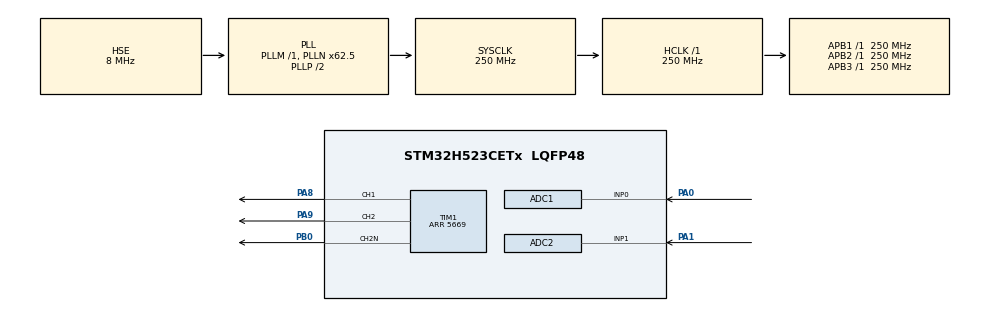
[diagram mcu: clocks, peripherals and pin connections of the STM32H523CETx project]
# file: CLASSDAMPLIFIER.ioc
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ADC1.Channel-0\#ChannelRegularConversion=ADC_CHANNEL_0
ADC1.ContinuousConvMode=DISABLE
ADC1.DMAContinuousRequests=ENABLE
ADC1.ExternalTrigConv=ADC_EXTERNALTRIG_T1_TRGO
ADC1.MonitoredBy-0\#ChannelRegularConversion=__NULL
ADC1.NbrOfConversion=1
ADC1.NbrOfConversionFlag=1
ADC1.OffsetNumber-0\#ChannelRegularConversion=ADC_OFFSET_NONE
ADC1.Rank-0\#ChannelRegularConversion=1
ADC1.SamplingTime-0\#ChannelRegularConversion=ADC_SAMPLETIME_2CYCLES_5
ADC1.master=1
ADC2.Channel-0\#ChannelRegularConversion=ADC_CHANNEL_1
ADC2.ContinuousConvMode=DISABLE
ADC2.EOCSelection=ADC_EOC_SINGLE_CONV
ADC2.MonitoredBy-0\#ChannelRegularConversion=__NULL
ADC2.NbrOfConversion=1
ADC2.NbrOfConversionFlag=1
ADC2.OffsetNumber-0\#ChannelRegularConversion=ADC_OFFSET_NONE
ADC2.Rank-0\#ChannelRegularConversion=1
ADC2.SamplingTime-0\#ChannelRegularConversion=ADC_SAMPLETIME_2CYCLES_5
BOOTPATH.BootPathName=LEGACY
BOOTPATH.UserSelectedBootPath=LEGACY
CORTEX_M33_NS.Number-Cortex_Memory_Protection_Unit_Region0_OTP_RO_AREAS_Settings=MPU_REGION_NUMBER0
CORTEX_M33_NS.default_mode_Activation=1
CORTEX_M33_NS.userName=CORTEX_M33
GPDMA1.CIRCULARMODE_GPDMACH0=ENABLE
GPDMA1.DESTDATAWIDTH_GPDMACH0=DMA_DEST_DATAWIDTH_HALFWORD
GPDMA1.IPHANDLE_GPDMACH0-SIMPLEREQUEST_GPDMACH0=__NULL
GPDMA1.REQUEST_GPDMACH0=GPDMA1_REQUEST_ADC1
GPDMA1.SRCDATAWIDTH_GPDMACH0=DMA_SRC_DATAWIDTH_HALFWORD
Mcu.Family=STM32H5
Mcu.Name=STM32H523CETx
Mcu.Package=LQFP48
NVIC.GPDMA1_Channel0_IRQn=true\:0\:0\:false\:false\:true\:false\:true\:true
NVIC.PriorityGroup=NVIC_PRIORITYGROUP_4
PA0.Signal=ADCx_INP0
PA1.Signal=ADCx_INP1
PA8.Signal=S_TIM1_CH1
PA9.Signal=S_TIM1_CH2
PB0.Mode=PWM Generation2 CH2 CH2N
PB0.Signal=TIM1_CH2N
PH0-OSC_IN(PH0).Mode=HSE-External-Oscillator
PH0-OSC_IN(PH0).Signal=RCC_OSC_IN
PH1-OSC_OUT(PH1).Mode=HSE-External-Oscillator
PH1-OSC_OUT(PH1).Signal=RCC_OSC_OUT
ProjectManager.HeapSize=0x200
ProjectManager.StackSize=0x400
ProjectManager.TargetToolchain=CMake
RCC.ADCFreq_Value=250000000
RCC.AHBFreq_Value=250000000
RCC.APB1Freq_Value=250000000
RCC.APB1TimFreq_Value=250000000
RCC.APB2Freq_Value=250000000
RCC.APB2TimFreq_Value=250000000
RCC.APB3Freq_Value=250000000
RCC.CSI_VALUE=4000000
RCC.CortexFreq_Value=250000000
RCC.EPOD_VALUE=8000000
RCC.HCLKFreq_Value=250000000
RCC.HSE_VALUE=8000000
RCC.HSI48_VALUE=48000000
RCC.HSI_VALUE=64000000
RCC.LSE_VALUE=32768
RCC.LSIRC_VALUE=32000
RCC.PLL2FRACN=0
RCC.PLL3FRACN=0
RCC.PLLFRACN=4096
RCC.PLLN=62
RCC.PLLSourceVirtual=RCC_PLL1_SOURCE_HSE
RCC.SYSCLKFreq_VALUE=250000000
RCC.SYSCLKSource=RCC_SYSCLKSOURCE_PLLCLK
RCC.USBFreq_Value=48000000
RCC.VCOOutputFreq_Value=500000000
SH.ADCx_INP0.0=ADC1_INP0,IN0-Single-Ended
SH.ADCx_INP1.0=ADC2_INP1,IN1-Single-Ended
SH.S_TIM1_CH1.0=TIM1_CH1,Output Compare1 CH1
SH.S_TIM1_CH2.0=TIM1_CH2,PWM Generation2 CH2 CH2N
TIM1.Channel-Output\ Compare1\ CH1=TIM_CHANNEL_1
TIM1.Channel-PWM\ Generation2\ CH2\ CH2N=TIM_CHANNEL_2
TIM1.DeadTime=50
TIM1.OCMode_1=TIM_OCMODE_TOGGLE
TIM1.PeriodNoDither=5669
TIM1.PulseNoDither_1=5668
TIM1.PulseNoDither_2=2834
TIM1.TIM_MasterOutputTrigger=TIM_TRGO_OC1REF
TIM1.TIM_MasterSlaveMode=TIM_MASTERSLAVEMODE_ENABLE
VP_BOOTPATH_VS_BOOTPATH.Mode=BP_Activate
VP_CORTEX_M33_NS_VS_Hclk.Mode=Hclk_Mode
VP_GPDMA1_VS_GPDMACH0.Mode=SIMPLEREQUEST_GPDMACH0
VP_ICACHE_VS_ICACHE.Mode=DirectMappedCache
VP_MEMORYMAP_VS_MEMORYMAP.Mode=CurAppReg
VP_PWR_VS_LPOM.Mode=PowerOptimisation
VP_PWR_VS_SECSignals.Mode=Security/Privilege
VP_TIM1_VS_ClockSourceINT.Mode=Internal
board=custom

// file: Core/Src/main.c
/* USER CODE BEGIN Header */
/**
  ******************************************************************************
  * @file           : main.c
  * @brief          : Main program body
  ******************************************************************************
  * @attention
  *
  * Copyright (c) 2026 STMicroelectronics.
  * All rights reserved.
  *
  * This software is licensed under terms that can be found in the LICENSE file
  * in the root directory of this software component.
  * If no LICENSE file comes with this software, it is provided AS-IS.
  *
  ******************************************************************************
  */
/* USER CODE END Header */
#include "main.h"

/* USER CODE BEGIN PD */
#define arr_value 5669//arr for 44.1kHz
#define INV_4095 (1.0f / 4095.0f*1.2f)
/* USER CODE END PD */

ADC_HandleTypeDef hadc1;
ADC_HandleTypeDef hadc2;
DMA_NodeTypeDef Node_GPDMA1_Channel0;
DMA_QListTypeDef List_GPDMA1_Channel0;
DMA_HandleTypeDef handle_GPDMA1_Channel0;

TIM_HandleTypeDef htim1;

/* USER CODE BEGIN PV */
volatile uint16_t adc_val[1];
float_t max_vol;
/* USER CODE END PV */

void SystemClock_Config(void);
static void MPU_Config(void);
static void MX_GPIO_Init(void);
static void MX_GPDMA1_Init(void);
static void MX_ADC1_Init(void);
static void MX_TIM1_Init(void);
static void MX_ICACHE_Init(void);
static void MX_ADC2_Init(void);

int main(void)
{

  /* USER CODE BEGIN 1 */
  //channel 1 of TIM1 is used to capture data from the adc
  //channel is used top generate PWM
  //PA9 CH2 PWM
  //PB0 CH2N PWM
  /* USER CODE END 1 */

  /* MCU Configuration--------------------------------------------------------*/

  /* MPU Configuration--------------------------------------------------------*/
  MPU_Config();

  /* Reset of all peripherals, Initializes the Flash interface and the Systick. */
  HAL_Init();

  /* Configure the system clock */
  SystemClock_Config();

  /* Initialize all configured peripherals */
  MX_GPIO_Init();
  MX_GPDMA1_Init();
  MX_ADC1_Init();
  MX_TIM1_Init();
  MX_ICACHE_Init();
  MX_ADC2_Init();
  /* USER CODE BEGIN 2 */
  HAL_ADC_Start_DMA(&hadc1, (uint32_t*)adc_val, 1);
  HAL_TIM_OC_Start(&htim1, TIM_CHANNEL_1);
  HAL_TIM_PWM_Start(&htim1, TIM_CHANNEL_3);
  HAL_TIMEx_PWMN_Start(&htim1, TIM_CHANNEL_3);

  /* USER CODE END 2 */

  /* Infinite loop */
  while (1)
  {

    /* USER CODE BEGIN 3 */
   HAL_ADC_Start(&hadc2);
    max_vol=((float_t)(HAL_ADC_GetValue(&hadc2)))*INV_4095;
    uint16_t pwm= (uint16_t)((max_vol*(float_t)adc_val[0]*(float_t)arr_value)*INV_4095);
  // adc_top is 4095 and arr_value is the top of duty cycle
  __HAL_TIM_SET_COMPARE(&htim1, TIM_CHANNEL_3,pwm);
//(adc_val*arr_value)/adc_top regladetres
  }
  /* USER CODE END 3 */
}

void SystemClock_Config(void)
{
  RCC_OscInitTypeDef RCC_OscInitStruct = {0};
  RCC_ClkInitTypeDef RCC_ClkInitStruct = {0};

  /** Configure the main internal regulator output voltage
  */
  __HAL_PWR_VOLTAGESCALING_CONFIG(PWR_REGULATOR_VOLTAGE_SCALE0);

  while(!__HAL_PWR_GET_FLAG(PWR_FLAG_VOSRDY)) {}

  /** Initializes the RCC Oscillators according to the specified parameters
  * in the RCC_OscInitTypeDef structure.
  */
  RCC_OscInitStruct.OscillatorType = RCC_OSCILLATORTYPE_HSE;
  RCC_OscInitStruct.HSEState = RCC_HSE_ON;
  RCC_OscInitStruct.PLL.PLLState = RCC_PLL_ON;
  RCC_OscInitStruct.PLL.PLLSource = RCC_PLL1_SOURCE_HSE;
  RCC_OscInitStruct.PLL.PLLM = 1;
  RCC_OscInitStruct.PLL.PLLN = 62;
  RCC_OscInitStruct.PLL.PLLP = 2;
  RCC_OscInitStruct.PLL.PLLQ = 2;
  RCC_OscInitStruct.PLL.PLLR = 2;
  RCC_OscInitStruct.PLL.PLLRGE = RCC_PLL1_VCIRANGE_3;
  RCC_OscInitStruct.PLL.PLLVCOSEL = RCC_PLL1_VCORANGE_WIDE;
  RCC_OscInitStruct.PLL.PLLFRACN = 4096;
  if (HAL_RCC_OscConfig(&RCC_OscInitStruct) != HAL_OK)
  {
    Error_Handler();
  }

  /** Initializes the CPU, AHB and APB buses clocks
  */
  RCC_ClkInitStruct.ClockType = RCC_CLOCKTYPE_HCLK|RCC_CLOCKTYPE_SYSCLK
                              |RCC_CLOCKTYPE_PCLK1|RCC_CLOCKTYPE_PCLK2
                              |RCC_CLOCKTYPE_PCLK3;
  RCC_ClkInitStruct.SYSCLKSource = RCC_SYSCLKSOURCE_PLLCLK;
  RCC_ClkInitStruct.AHBCLKDivider = RCC_SYSCLK_DIV1;
  RCC_ClkInitStruct.APB1CLKDivider = RCC_HCLK_DIV1;
  RCC_ClkInitStruct.APB2CLKDivider = RCC_HCLK_DIV1;
  RCC_ClkInitStruct.APB3CLKDivider = RCC_HCLK_DIV1;

  if (HAL_RCC_ClockConfig(&RCC_ClkInitStruct, FLASH_LATENCY_5) != HAL_OK)
  {
    Error_Handler();
  }

  /** Configure the programming delay
  */
  __HAL_FLASH_SET_PROGRAM_DELAY(FLASH_PROGRAMMING_DELAY_2);
}

static void MX_ADC1_Init(void)
{

  ADC_ChannelConfTypeDef sConfig = {0};

  /** Common config
  */
  hadc1.Instance = ADC1;
  hadc1.Init.ClockPrescaler = ADC_CLOCK_ASYNC_DIV4;
  hadc1.Init.Resolution = ADC_RESOLUTION_12B;
  hadc1.Init.DataAlign = ADC_DATAALIGN_RIGHT;
  hadc1.Init.ScanConvMode = ADC_SCAN_DISABLE;
  hadc1.Init.EOCSelection = ADC_EOC_SINGLE_CONV;
  hadc1.Init.LowPowerAutoWait = DISABLE;
  hadc1.Init.ContinuousConvMode = DISABLE;
  hadc1.Init.NbrOfConversion = 1;
  hadc1.Init.DiscontinuousConvMode = DISABLE;
  hadc1.Init.ExternalTrigConv = ADC_EXTERNALTRIG_T1_TRGO;
  hadc1.Init.ExternalTrigConvEdge = ADC_EXTERNALTRIGCONVEDGE_RISING;
  hadc1.Init.DMAContinuousRequests = ENABLE;
  hadc1.Init.SamplingMode = ADC_SAMPLING_MODE_NORMAL;
  hadc1.Init.Overrun = ADC_OVR_DATA_PRESERVED;
  hadc1.Init.OversamplingMode = DISABLE;
  if (HAL_ADC_Init(&hadc1) != HAL_OK)
  {
    Error_Handler();
  }

  /** Configure Regular Channel
  */
  sConfig.Channel = ADC_CHANNEL_0;
  sConfig.Rank = ADC_REGULAR_RANK_1;
  sConfig.SamplingTime = ADC_SAMPLETIME_2CYCLES_5;
  sConfig.SingleDiff = ADC_SINGLE_ENDED;
  sConfig.OffsetNumber = ADC_OFFSET_NONE;
  sConfig.Offset = 0;
  if (HAL_ADC_ConfigChannel(&hadc1, &sConfig) != HAL_OK)
  {
    Error_Handler();
  }

}

static void MX_ADC2_Init(void)
{

  ADC_ChannelConfTypeDef sConfig = {0};

  /** Common config
  */
  hadc2.Instance = ADC2;
  hadc2.Init.ClockPrescaler = ADC_CLOCK_ASYNC_DIV4;
  hadc2.Init.Resolution = ADC_RESOLUTION_12B;
  hadc2.Init.DataAlign = ADC_DATAALIGN_RIGHT;
  hadc2.Init.ScanConvMode = ADC_SCAN_DISABLE;
  hadc2.Init.EOCSelection = ADC_EOC_SINGLE_CONV;
  hadc2.Init.LowPowerAutoWait = DISABLE;
  hadc2.Init.ContinuousConvMode = DISABLE;
  hadc2.Init.NbrOfConversion = 1;
  hadc2.Init.DiscontinuousConvMode = DISABLE;
  hadc2.Init.ExternalTrigConv = ADC_SOFTWARE_START;
  hadc2.Init.ExternalTrigConvEdge = ADC_EXTERNALTRIGCONVEDGE_NONE;
  hadc2.Init.DMAContinuousRequests = DISABLE;
  hadc2.Init.SamplingMode = ADC_SAMPLING_MODE_NORMAL;
  hadc2.Init.Overrun = ADC_OVR_DATA_PRESERVED;
  hadc2.Init.OversamplingMode = DISABLE;
  if (HAL_ADC_Init(&hadc2) != HAL_OK)
  {
    Error_Handler();
  }

  /** Configure Regular Channel
  */
  sConfig.Channel = ADC_CHANNEL_1;
  sConfig.Rank = ADC_REGULAR_RANK_1;
  sConfig.SamplingTime = ADC_SAMPLETIME_2CYCLES_5;
  sConfig.SingleDiff = ADC_SINGLE_ENDED;
  sConfig.OffsetNumber = ADC_OFFSET_NONE;
  sConfig.Offset = 0;
  if (HAL_ADC_ConfigChannel(&hadc2, &sConfig) != HAL_OK)
  {
    Error_Handler();
  }

}

static void MX_GPDMA1_Init(void)
{

  /* Peripheral clock enable */
  __HAL_RCC_GPDMA1_CLK_ENABLE();

  /* GPDMA1 interrupt Init */
    HAL_NVIC_SetPriority(GPDMA1_Channel0_IRQn, 0, 0);
    HAL_NVIC_EnableIRQ(GPDMA1_Channel0_IRQn);

}

static void MX_ICACHE_Init(void)
{

  /** Enable instruction cache in 1-way (direct mapped cache)
  */
  if (HAL_ICACHE_ConfigAssociativityMode(ICACHE_1WAY) != HAL_OK)
  {
    Error_Handler();
  }
  if (HAL_ICACHE_Enable() != HAL_OK)
  {
    Error_Handler();
  }

}

static void MX_TIM1_Init(void)
{

  TIM_ClockConfigTypeDef sClockSourceConfig = {0};
  TIM_MasterConfigTypeDef sMasterConfig = {0};
  TIM_OC_InitTypeDef sConfigOC = {0};
  TIM_BreakDeadTimeConfigTypeDef sBreakDeadTimeConfig = {0};

  htim1.Instance = TIM1;
  htim1.Init.Prescaler = 0;
  htim1.Init.CounterMode = TIM_COUNTERMODE_UP;
  htim1.Init.Period = 5669;
  htim1.Init.ClockDivision = TIM_CLOCKDIVISION_DIV1;
  htim1.Init.RepetitionCounter = 0;
  htim1.Init.AutoReloadPreload = TIM_AUTORELOAD_PRELOAD_DISABLE;
  if (HAL_TIM_Base_Init(&htim1) != HAL_OK)
  {
    Error_Handler();
  }
  sClockSourceConfig.ClockSource = TIM_CLOCKSOURCE_INTERNAL;
  if (HAL_TIM_ConfigClockSource(&htim1, &sClockSourceConfig) != HAL_OK)
  {
    Error_Handler();
  }
  if (HAL_TIM_OC_Init(&htim1) != HAL_OK)
  {
    Error_Handler();
  }
  if (HAL_TIM_PWM_Init(&htim1) != HAL_OK)
  {
    Error_Handler();
  }
  sMasterConfig.MasterOutputTrigger = TIM_TRGO_OC1REF;
  sMasterConfig.MasterOutputTrigger2 = TIM_TRGO2_RESET;
  sMasterConfig.MasterSlaveMode = TIM_MASTERSLAVEMODE_ENABLE;
  if (HAL_TIMEx_MasterConfigSynchronization(&htim1, &sMasterConfig) != HAL_OK)
  {
    Error_Handler();
  }
  sConfigOC.OCMode = TIM_OCMODE_TOGGLE;
  sConfigOC.Pulse = 5668;
  sConfigOC.OCPolarity = TIM_OCPOLARITY_HIGH;
  sConfigOC.OCNPolarity = TIM_OCNPOLARITY_HIGH;
  sConfigOC.OCFastMode = TIM_OCFAST_DISABLE;
  sConfigOC.OCIdleState = TIM_OCIDLESTATE_RESET;
  sConfigOC.OCNIdleState = TIM_OCNIDLESTATE_RESET;
  if (HAL_TIM_OC_ConfigChannel(&htim1, &sConfigOC, TIM_CHANNEL_1) != HAL_OK)
  {
    Error_Handler();
  }
  sConfigOC.OCMode = TIM_OCMODE_PWM1;
  sConfigOC.Pulse = 0;
  if (HAL_TIM_PWM_ConfigChannel(&htim1, &sConfigOC, TIM_CHANNEL_3) != HAL_OK)
  {
    Error_Handler();
  }
  sBreakDeadTimeConfig.OffStateRunMode = TIM_OSSR_DISABLE;
  sBreakDeadTimeConfig.OffStateIDLEMode = TIM_OSSI_DISABLE;
  sBreakDeadTimeConfig.LockLevel = TIM_LOCKLEVEL_OFF;
  sBreakDeadTimeConfig.DeadTime = 10;
  sBreakDeadTimeConfig.BreakState = TIM_BREAK_DISABLE;
  sBreakDeadTimeConfig.BreakPolarity = TIM_BREAKPOLARITY_HIGH;
  sBreakDeadTimeConfig.BreakFilter = 0;
  sBreakDeadTimeConfig.BreakAFMode = TIM_BREAK_AFMODE_INPUT;
  sBreakDeadTimeConfig.Break2State = TIM_BREAK2_DISABLE;
  sBreakDeadTimeConfig.Break2Polarity = TIM_BREAK2POLARITY_HIGH;
  sBreakDeadTimeConfig.Break2Filter = 0;
  sBreakDeadTimeConfig.Break2AFMode = TIM_BREAK_AFMODE_INPUT;
  sBreakDeadTimeConfig.AutomaticOutput = TIM_AUTOMATICOUTPUT_DISABLE;
  if (HAL_TIMEx_ConfigBreakDeadTime(&htim1, &sBreakDeadTimeConfig) != HAL_OK)
  {
    Error_Handler();
  }
  HAL_TIM_MspPostInit(&htim1);

}

static void MX_GPIO_Init(void)
{

  /* GPIO Ports Clock Enable */
  __HAL_RCC_GPIOH_CLK_ENABLE();
  __HAL_RCC_GPIOA_CLK_ENABLE();
  __HAL_RCC_GPIOB_CLK_ENABLE();

}

 /* MPU Configuration */

void MPU_Config(void)
{
  MPU_Region_InitTypeDef MPU_InitStruct = {0};
  MPU_Attributes_InitTypeDef MPU_AttributesInit = {0};

  /* Disables the MPU */
  HAL_MPU_Disable();

  /** Initializes and configures the Region 0 and the memory to be protected
  */
  MPU_InitStruct.Enable = MPU_REGION_ENABLE;
  MPU_InitStruct.Number = MPU_REGION_NUMBER0;
  MPU_InitStruct.BaseAddress = 0x08FFF000;
  MPU_InitStruct.LimitAddress = 0x08FFFFFF;
  MPU_InitStruct.AttributesIndex = MPU_ATTRIBUTES_NUMBER0;
  MPU_InitStruct.AccessPermission = MPU_REGION_ALL_RO;
  MPU_InitStruct.DisableExec = MPU_INSTRUCTION_ACCESS_DISABLE;
  MPU_InitStruct.IsShareable = MPU_ACCESS_NOT_SHAREABLE;

  HAL_MPU_ConfigRegion(&MPU_InitStruct);

  /** Initializes and configures the Attribute 0 and the memory to be protected
  */
  MPU_AttributesInit.Number = MPU_ATTRIBUTES_NUMBER0;
  MPU_AttributesInit.Attributes = INNER_OUTER(MPU_NOT_CACHEABLE);

  HAL_MPU_ConfigMemoryAttributes(&MPU_AttributesInit);
  /* Enables the MPU */
  HAL_MPU_Enable(MPU_PRIVILEGED_DEFAULT);

}

void Error_Handler(void)
{
  __disable_irq();
  while (1)
  {
  }
}
